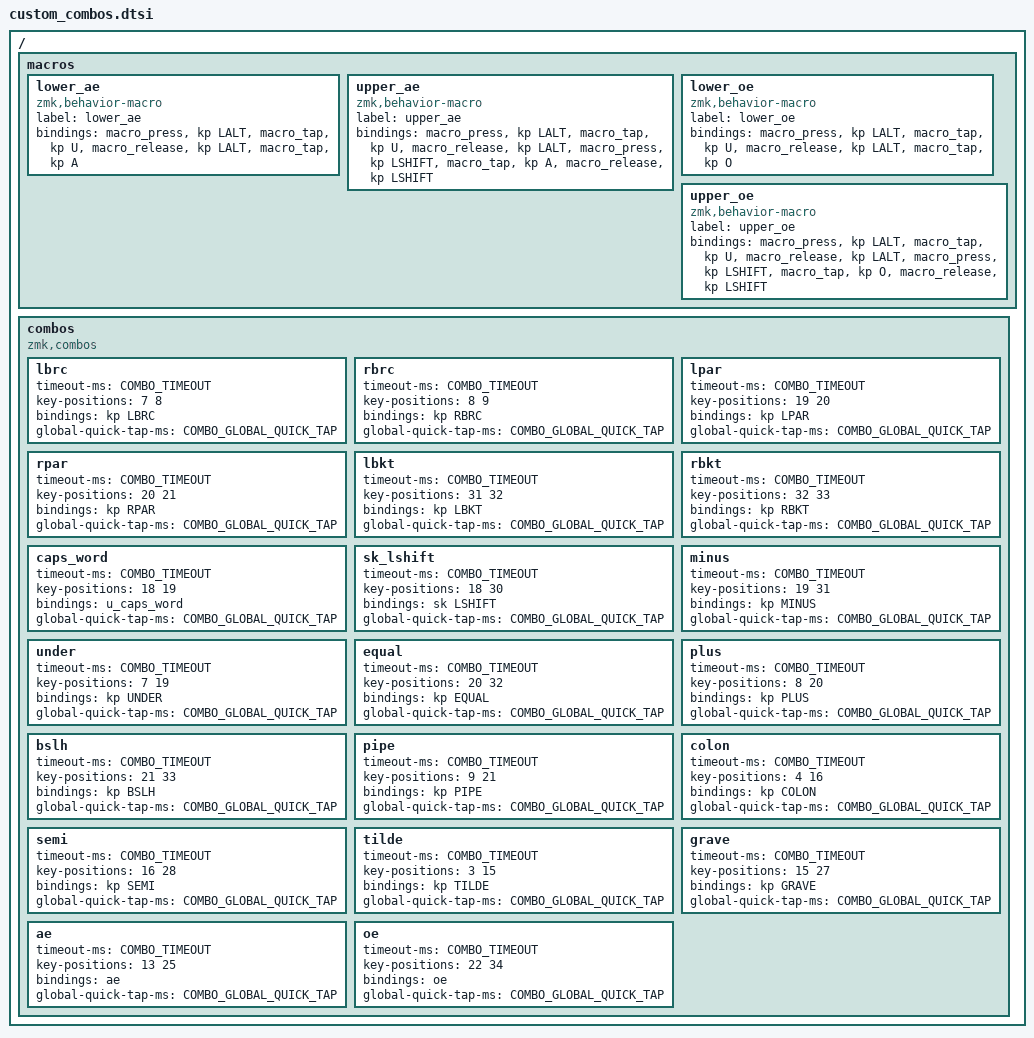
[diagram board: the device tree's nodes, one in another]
/*            KEY POSITIONS
  ╭────────────────╮ ╭────────────────╮
  │  1  2  3  4  5 │ │  6  7  8  9 10 │
  │ 13 14 15 16 17 │ │ 18 19 20 21 22 │
  │ 25 26 27 28 29 │ │ 30 31 32 33 34 │
  ╰─────╮ 36 37 38 │ │ 39 40 41 ╭─────╯
        ╰──────────╯ ╰──────────╯      */
#define COMBO_TIMEOUT 25
#define COMBO_GLOBAL_QUICK_TAP 75

/ {
    macros {
        lower_ae: lower_ae {
            label = "lower_ae";
            compatible = "zmk,behavior-macro";
            #binding-cells = <0>;
            bindings
                = <&macro_press &kp LALT>
                , <&macro_tap &kp U>
                , <&macro_release &kp LALT>
                , <&macro_tap &kp A>
                ;
        };
        upper_ae: upper_ae {
            label = "upper_ae";
            compatible = "zmk,behavior-macro";
            #binding-cells = <0>;
            bindings
                = <&macro_press &kp LALT>
                , <&macro_tap &kp U>
                , <&macro_release &kp LALT>
                , <&macro_press &kp LSHIFT>
                , <&macro_tap &kp A>
                , <&macro_release &kp LSHIFT>
                ;
        };
        lower_oe: lower_oe {
            label = "lower_oe";
            compatible = "zmk,behavior-macro";
            #binding-cells = <0>;
            bindings
                = <&macro_press &kp LALT>
                , <&macro_tap &kp U>
                , <&macro_release &kp LALT>
                , <&macro_tap &kp O>
                ;
        };
        upper_oe: upper_oe {
            label = "upper_oe";
            compatible = "zmk,behavior-macro";
            #binding-cells = <0>;
            bindings
                = <&macro_press &kp LALT>
                , <&macro_tap &kp U>
                , <&macro_release &kp LALT>
                , <&macro_press &kp LSHIFT>
                , <&macro_tap &kp O>
                , <&macro_release &kp LSHIFT>
                ;
        };
    };
};

/ {
    combos {
        compatible = "zmk,combos";
        // Right hand horizontal
        lbrc {
            timeout-ms = <COMBO_TIMEOUT>;
            key-positions = <7 8>;
            bindings = <&kp LBRC>;
            global-quick-tap-ms = <COMBO_GLOBAL_QUICK_TAP>;
        };
        rbrc {
            timeout-ms = <COMBO_TIMEOUT>;
            key-positions = <8 9>;
            bindings = <&kp RBRC>;
            global-quick-tap-ms = <COMBO_GLOBAL_QUICK_TAP>;
        };
        lpar {
            timeout-ms = <COMBO_TIMEOUT>;
            key-positions = <19 20>;
            bindings = <&kp LPAR>;
            global-quick-tap-ms = <COMBO_GLOBAL_QUICK_TAP>;
        };
        rpar {
            timeout-ms = <COMBO_TIMEOUT>;
            key-positions = <20 21>;
            bindings = <&kp RPAR>;
            global-quick-tap-ms = <COMBO_GLOBAL_QUICK_TAP>;
        };
        lbkt {
            timeout-ms = <COMBO_TIMEOUT>;
            key-positions = <31 32>;
            bindings = <&kp LBKT>;
            global-quick-tap-ms = <COMBO_GLOBAL_QUICK_TAP>;
        };
        rbkt {
            timeout-ms = <COMBO_TIMEOUT>;
            key-positions = <32 33>;
            bindings = <&kp RBKT>;
            global-quick-tap-ms = <COMBO_GLOBAL_QUICK_TAP>;
        };
        caps_word {
            timeout-ms = <COMBO_TIMEOUT>;
            key-positions = <18 19>;
            bindings = <&u_caps_word>;
            global-quick-tap-ms = <COMBO_GLOBAL_QUICK_TAP>;
        };
        // Right hand vertical
        sk_lshift {
            timeout-ms = <COMBO_TIMEOUT>;
            key-positions = <18 30>;
            bindings = <&sk LSHIFT>;
            global-quick-tap-ms = <COMBO_GLOBAL_QUICK_TAP>;
        };
        minus {
            timeout-ms = <COMBO_TIMEOUT>;
            key-positions = <19 31>;
            bindings = <&kp MINUS>;
            global-quick-tap-ms = <COMBO_GLOBAL_QUICK_TAP>;
        };
        under {
            timeout-ms = <COMBO_TIMEOUT>;
            key-positions = <7 19>;
            bindings = <&kp UNDER>;
            global-quick-tap-ms = <COMBO_GLOBAL_QUICK_TAP>;
        };
        equal {
            timeout-ms = <COMBO_TIMEOUT>;
            key-positions = <20 32>;
            bindings = <&kp EQUAL>;
            global-quick-tap-ms = <COMBO_GLOBAL_QUICK_TAP>;
        };
        plus {
            timeout-ms = <COMBO_TIMEOUT>;
            key-positions = <8 20>;
            bindings = <&kp PLUS>;
            global-quick-tap-ms = <COMBO_GLOBAL_QUICK_TAP>;
        };
        bslh {
            timeout-ms = <COMBO_TIMEOUT>;
            key-positions = <21 33>;
            bindings = <&kp BSLH>;
            global-quick-tap-ms = <COMBO_GLOBAL_QUICK_TAP>;
        };
        pipe {
            timeout-ms = <COMBO_TIMEOUT>;
            key-positions = <9 21>;
            bindings = <&kp PIPE>;
            global-quick-tap-ms = <COMBO_GLOBAL_QUICK_TAP>;
        };
        // Left hand vertical
        colon {
            timeout-ms = <COMBO_TIMEOUT>;
            key-positions = <4 16>;
            bindings = <&kp COLON>;
            global-quick-tap-ms = <COMBO_GLOBAL_QUICK_TAP>;
        };
        semi {
            timeout-ms = <COMBO_TIMEOUT>;
            key-positions = <16 28>;
            bindings = <&kp SEMI>;
            global-quick-tap-ms = <COMBO_GLOBAL_QUICK_TAP>;
        };
        tilde {
            timeout-ms = <COMBO_TIMEOUT>;
            key-positions = <3 15>;
            bindings = <&kp TILDE>;
            global-quick-tap-ms = <COMBO_GLOBAL_QUICK_TAP>;
        };
        grave {
            timeout-ms = <COMBO_TIMEOUT>;
            key-positions = <15 27>;
            bindings = <&kp GRAVE>;
            global-quick-tap-ms = <COMBO_GLOBAL_QUICK_TAP>;
        };
        ae {
            timeout-ms = <COMBO_TIMEOUT>;
            key-positions = <13 25>;
            bindings = <&ae>;
            global-quick-tap-ms = <COMBO_GLOBAL_QUICK_TAP>;
        };
        oe {
            timeout-ms = <COMBO_TIMEOUT>;
            key-positions = <22 34>;
            bindings = <&oe>;
            global-quick-tap-ms = <COMBO_GLOBAL_QUICK_TAP>;
        };
    };
};
